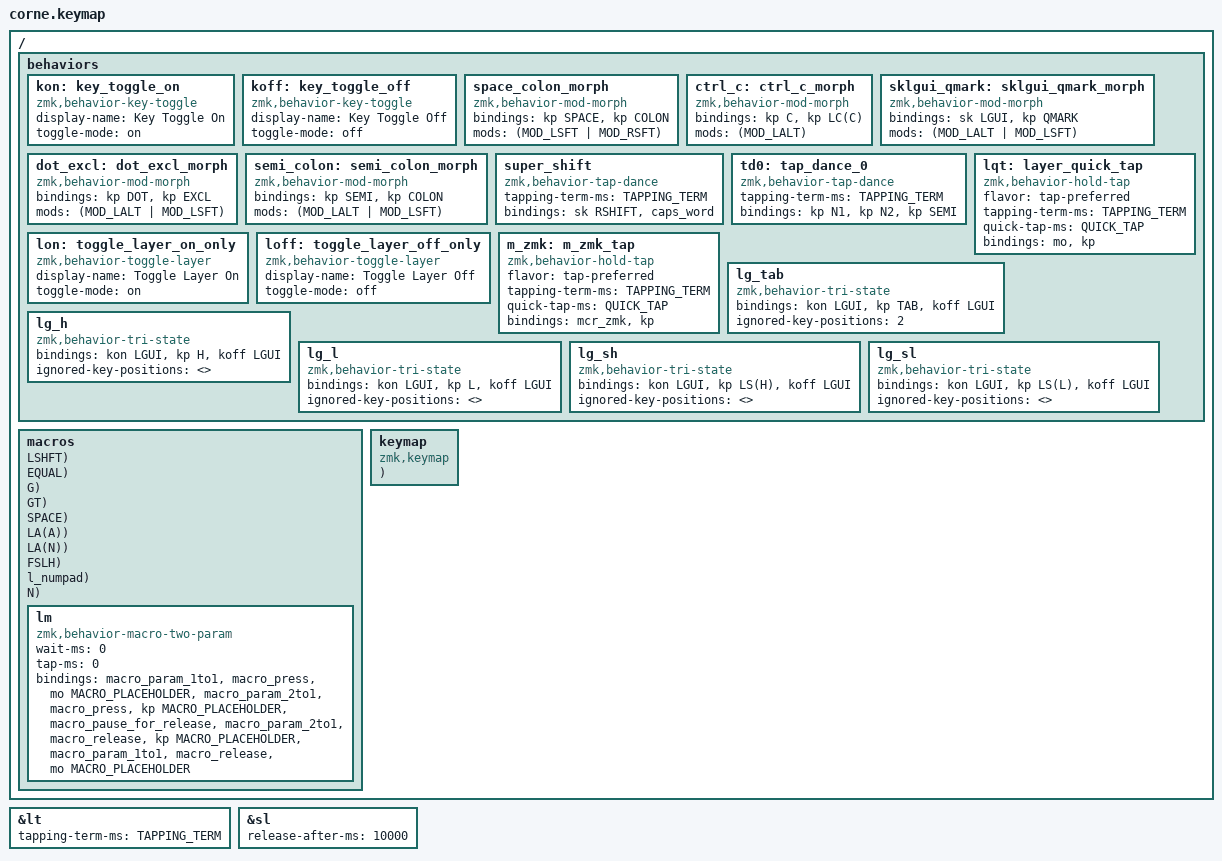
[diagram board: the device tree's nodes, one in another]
#include <behaviors.dtsi>
#include <dt-bindings/zmk/keys.h>
#include <dt-bindings/zmk/bt.h>

#define STRINGIFY(x) #x
#define EXPAND_AND_STRINGIFY(x) STRINGIFY(x)
#define MACRO(NAME, BINDINGS) \
mcr_##NAME: mcr_##NAME { \
   compatible = "zmk,behavior-macro"; \
   #binding-cells = <0>; \
   wait-ms = <20>; \
   tap-ms = <10>; \
   bindings = <BINDINGS>; \
}

#define hands(layer_name, \
   lt1, lt2, lt3, lt4, lt5, lt6, lm1, lm2, lm3, lm4, lm5, lm6, lb1, lb2, lb3, lb4, lb5, lb6, lth1, lth2, lth3, \
   rt1, rt2, rt3, rt4, rt5, rt6, rm1, rm2, rm3, rm4, rm5, rm6, rb1, rb2, rb3, rb4, rb5, rb6, rth1, rth2, rth3 \
) \
layer_name { \
   display-name = EXPAND_AND_STRINGIFY(layer_name); \
   bindings = < \
      lt1 lt2 lt3 lt4 lt5 lt6 rt1 rt2 rt3 rt4 rt5 rt6 lm1 lm2 lm3 lm4 lm5 lm6 \
      rm1 rm2 rm3 rm4 rm5 rm6 lb1 lb2 lb3 lb4 lb5 lb6 rb1 rb2 rb3 rb4 rb5 rb6 \
      lth1 lth2 lth3 rth1 rth2 rth3 \
   >; \
}

#define right(layer_name, \
   rt1, rt2, rt3, rt4, rt5, rt6, rm1, rm2, rm3, rm4, rm5, rm6, rb1, rb2, rb3, rb4, rb5, rb6, rth1, rth2, rth3 \
) \
layer_name { \
   display-name = EXPAND_AND_STRINGIFY(layer_name); \
   bindings = < \
      &trans     &trans &trans &trans &trans &trans rt1 rt2 rt3 rt4 rt5 rt6 \
      &to l_base &trans &trans &trans &trans &trans rm1 rm2 rm3 rm4 rm5 rm6 \
      &trans     &trans &trans &trans &trans &trans rb1 rb2 rb3 rb4 rb5 rb6 \
      &trans     &trans &trans rth1 rth2 rth3 \
   >; \
}

#define left(layer_name, \
   lt1, lt2, lt3, lt4, lt5, lt6, lm1, lm2, lm3, lm4, lm5, lm6, lb1, lb2, lb3, lb4, lb5, lb6, lth1, lth2, lth3 \
) \
layer_name { \
   display-name = EXPAND_AND_STRINGIFY(layer_name); \
   bindings = < \
      lt1 lt2 lt3 lt4 lt5 lt6 &trans &trans &trans &trans &trans &trans \
      lm1 lm2 lm3 lm4 lm5 lm6 &trans &trans &trans &trans &trans &trans \
      lb1 lb2 lb3 lb4 lb5 lb6 &trans &trans &trans &trans &trans &trans \
      lth1 lth2 lth3 &trans &trans &trans \
   >; \
}

#define l_base       0
#define l_reright    1
#define l_releft     2
#define l_code1      3
#define l_code2      4
#define l_term       5
#define l_symb1      6
#define l_symb2      7
#define l_os1        8
#define l_numpad     9
#define l_vimnav    10
#define l_arrows    11
#define l_toglayer  12

#define PRIOR_IDLE 125
#define TAPPING_TERM 200
#define QUICK_TAP 300

// #define PRIOR_IDLE 125
// #define TAPPING_TERM 250

// &mt {
   // tapping-term-ms = <TAPPING_TERM>;
   // require-prior-idle-ms = <PRIOR_IDLE>;
// };

&lt {
   tapping-term-ms = <TAPPING_TERM>;
   // require-prior-idle-ms = <PRIOR_IDLE>;
};

&sl {
    release-after-ms = <10000>;
};

/ {

   behaviors {
      kon: key_toggle_on {
         compatible = "zmk,behavior-key-toggle";
         #binding-cells = <1>;
         display-name = "Key Toggle On";
         toggle-mode = "on";
      };
      koff: key_toggle_off {
         compatible = "zmk,behavior-key-toggle";
         #binding-cells = <1>;
         display-name = "Key Toggle Off";
         toggle-mode = "off";
      };
      space_colon_morph: space_colon_morph {
         compatible = "zmk,behavior-mod-morph";
         #binding-cells = <0>;
         bindings = <&kp SPACE>, <&kp COLON>;
         mods = <(MOD_LSFT | MOD_RSFT)>;
      };
      ctrl_c: ctrl_c_morph {
         compatible = "zmk,behavior-mod-morph";
         #binding-cells = <0>;
         bindings = <&kp C>, <&kp LC(C)>;
         mods = <(MOD_LALT)>;
      };
      sklgui_qmark: sklgui_qmark_morph {
         compatible = "zmk,behavior-mod-morph";
         #binding-cells = <0>;
         bindings = <&sk LGUI>, <&kp QMARK>;
         mods = <(MOD_LALT | MOD_LSFT)>;
      };
      dot_excl: dot_excl_morph {
         compatible = "zmk,behavior-mod-morph";
         #binding-cells = <0>;
         bindings = <&kp DOT>, <&kp EXCL>;
         mods = <(MOD_LALT | MOD_LSFT)>;
      };
      semi_colon: semi_colon_morph {
         compatible = "zmk,behavior-mod-morph";
         #binding-cells = <0>;
         bindings = <&kp SEMI>, <&kp COLON>;
         mods = <(MOD_LALT | MOD_LSFT)>;
      };
      super_shift: super_shift {
         compatible = "zmk,behavior-tap-dance";
         #binding-cells = <0>;
         tapping-term-ms = <TAPPING_TERM>;
         bindings = <&sk RSHIFT>, <&caps_word>;
      };
      td0: tap_dance_0 {
         compatible = "zmk,behavior-tap-dance";
         #binding-cells = <0>;
         tapping-term-ms = <TAPPING_TERM>;
         bindings = <&kp N1>, <&kp N2>, <&kp SEMI>;
      };
      lqt: layer_quick_tap {
         compatible = "zmk,behavior-hold-tap";
         #binding-cells = <2>;
         flavor = "tap-preferred";
         tapping-term-ms = <TAPPING_TERM>;
         quick-tap-ms = <QUICK_TAP>;
         bindings = <&mo>, <&kp>;
      };
      lon: toggle_layer_on_only {
         compatible = "zmk,behavior-toggle-layer";
         #binding-cells = <1>;
         display-name = "Toggle Layer On";
         toggle-mode = "on";
      };
      loff: toggle_layer_off_only {
         compatible = "zmk,behavior-toggle-layer";
         #binding-cells = <1>;
         display-name = "Toggle Layer Off";
         toggle-mode = "off";
      };
      m_zmk: m_zmk_tap {
         compatible = "zmk,behavior-hold-tap";
         #binding-cells = <2>;
         flavor = "tap-preferred";
         tapping-term-ms = <TAPPING_TERM>;
         quick-tap-ms = <QUICK_TAP>;
         bindings = <&mcr_zmk>, <&kp>;
      };
      lg_tab: lg_tab {
         compatible = "zmk,behavior-tri-state";
         #binding-cells = <0>;
         bindings = <&kon LGUI>, <&kp TAB>, <&koff LGUI>;
         ignored-key-positions = <2>;
      };
      // this almost works but an extra koff gets queued on only one direction and eats the next lgui
      // ls_lg_tab: ls_lg_tab {
         // compatible = "zmk,behavior-tri-state";
         // #binding-cells = <0>;
         // bindings = <&kon LGUI>, <&kp LS(TAB)>, <&mcr_lgoff>;
         // ignored-key-positions = <3>;
      // };
      lg_h: lg_h {
         compatible = "zmk,behavior-tri-state";
         #binding-cells = <0>;
         bindings = <&kon LGUI>, <&kp H>, <&koff LGUI>;
         ignored-key-positions = <>;
      };
      lg_l: lg_l {
         compatible = "zmk,behavior-tri-state";
         #binding-cells = <0>;
         bindings = <&kon LGUI>, <&kp L>, <&koff LGUI>;
         ignored-key-positions = <>;
      };
      lg_sh: lg_sh {
         compatible = "zmk,behavior-tri-state";
         #binding-cells = <0>;
         bindings = <&kon LGUI>, <&kp LS(H)>, <&koff LGUI>;
         ignored-key-positions = <>;
      };
      lg_sl: lg_sl {
         compatible = "zmk,behavior-tri-state";
         #binding-cells = <0>;
         bindings = <&kon LGUI>, <&kp LS(L)>, <&koff LGUI>;
         ignored-key-positions = <>;
      };
      // num_td_a: num_td_a {
         // compatible = "zmk,behavior-tap-dance";
         // label = "num_td";
         // #binding-cells = <0>;
         // tapping-term-ms = <TAPPING_TERM>;
         // bindings =
            // <&lt l_numpad A>,
            // <&lon l_numpad>;
      // };
      // alt_a_td_fix: alt_a_td_fix {
         // compatible = "zmk,behavior-mod-morph";
         // #binding-cells = <0>;
         // bindings =  <&num_td_a>, <&kp LA(A)>;
         // mods = <MOD_LALT>;
      // };
   };

   macros {
      MACRO(zmk, &macro_press &kp LSHFT &macro_tap &kp Z &kp M &kp K &macro_release &kp LSHFT);
      MACRO(shift_tab, &macro_press &kp LSHFT &macro_tap &kp TAB &macro_release &kp LSHFT);
      MACRO(seq, &macro_tap &kp EQUAL &kp EQUAL &kp EQUAL);
      MACRO(sne, &macro_tap &kp EXCL &kp EQUAL &kp EQUAL);
      MACRO(lte, &macro_tap &kp LT &kp EQUAL);
      MACRO(gte, &macro_tap &kp GT &kp EQUAL);
      MACRO(gg, &macro_tap &kp G &kp G);
      MACRO(peq, &macro_tap &kp PLUS &kp EQUAL);
      MACRO(meq, &macro_tap &kp MINUS &kp EQUAL);
      MACRO(arwfn, &macro_tap &kp EQUAL &kp GT);
      MACRO(the, &macro_tap &kp T &kp H &kp E &kp SPACE);
      MACRO(ca_ca, &macro_tap &kp LA(A) &kp LA(A));
      MACRO(ca_cn, &macro_tap &kp LA(A) &kp LA(N));
      MACRO(dot_fs, &macro_tap &kp DOT &kp FSLH);
      MACRO(goto_line, &macro_tap &kp SEMI &kp L &kp L &to l_numpad);
      MACRO(endl, &macro_tap &kp BSLH &kp N);
      // MACRO(lgoff, &macro_tap &koff LGUI &koff LGUI);
      /**
      * Temporarily switches to a layer (`&mo`) while a modifier is held.
      * Analogous to QMK's `LM()`, using a parameterized macro.
      *
      * Params:
      *  1. Layer to switch to
      *  2. Modifier to press while layer is active
      *
      * Example:
      *  `&lm NUM_LAYER LSHIFT`
      */
      lm: lm {
         compatible = "zmk,behavior-macro-two-param";
         wait-ms = <0>;
         tap-ms = <0>;
         #binding-cells = <2>;
         bindings
         = <&macro_param_1to1>
         , <&macro_press &mo MACRO_PLACEHOLDER>
         , <&macro_param_2to1>
         , <&macro_press &kp MACRO_PLACEHOLDER>
         , <&macro_pause_for_release>
         , <&macro_param_2to1>
         , <&macro_release &kp MACRO_PLACEHOLDER>
         , <&macro_param_1to1>
         , <&macro_release &mo MACRO_PLACEHOLDER>
         ;
      };
   };

   keymap {

      compatible = "zmk,keymap";

      hands( base,

         &kp TAB       , &lt l_os1 Q    , &kp W          , &lt l_arrows E , &kp R           , &kp T         ,
         &mt LALT ESC  , &lt l_numpad A , &lt l_term S   , &lqt l_code2 D , &lt l_code1 F   , &kp G         ,
         &super_shift  , &kp Z          , &kp X          , &ctrl_c        , &lt l_reright V , &kp B         ,
         &sk LGUI      , &kp SPACE      , &kp SPACE      ,
         // &none      , &none          , &none          ,
         // &none      , &kp SPACE      , &none          ,
         // &kp LGUI   , &kp SPACE      , &kp LALT       ,

         &kp Y        , &kp U          , &kp I          , &kp O          , &kp P           , &lon l_vimnav ,
         &kp H        , &lqt l_symb1 J , &lqt l_symb2 K , &kp L          , &semi_colon     , &sl l_toglayer,
         &kp N        , &lt l_releft M , &kp COMMA      , &dot_excl      , &sklgui_qmark   , &none         ,
         &none        , &none          , &none
         // &lm l_releft LGUI , &none          , &none
         // &none             , &none          , &none
         // &kp SPACE         , &kp SPACE      , &kp SPACE
         // &kp SPACE         , &none          , &none
         // &none             , &none          , &none
         // &kp SPACE         , &ctrlentbspc   , &kp RGUI

         /*&trans,&trans,&trans,&trans,&trans,&trans,*/
         /*&trans,&trans,&trans,&trans,&trans,&trans,*/
         /*&trans,&trans,&trans,&trans,&trans,&trans,*/
         /*&trans,&trans,&trans,*/
         /*&trans,&trans,&trans,&trans,&trans,&trans,*/
         /*&trans,&trans,&trans,&trans,&trans,&trans,*/
         /*&trans,&trans,&trans,&trans,&trans,&trans,*/
         /*&trans,&trans,&trans*/

      );

      right( reright,
         &none  , &none        , &kp LC(U) , &none       , &none    , &none ,
         &none  , &kp BSPC     , &kp RET   , &kp LA(H)   , &kp FSLH , &none ,
         &none  , &kp LA(BSPC) , &kp LC(D) , &mcr_dot_fs , &none    , &none ,
         &trans , &trans       , &trans
      );

      hands( releft,
         // &none , &none             , &kp LS(LG(TAB)) , &kp LG(TAB)       , &none         , &none      ,
         // &none , &kp LG(H)         , &kp LA(H)       , &kp LA(L)         , &kp LG(L)     , &none      ,
         // &none , &none             , &none           , &kp LS(LA(LG(K))) , &kp LA(LG(K)) , &none      ,

         &none    , &lg_sh            , &kp LS(TAB)     , &lg_tab           , &lg_sl        , &none      ,
         &none    , &lg_h             , &kp LA(H)       , &kp LA(L)         , &lg_l         , &none      ,
         &none    , &kp LS(LA(LG(Z))) , &none           , &kp LA(LG(Z))     , &mcr_ca_ca    , &mcr_ca_cn ,
         &trans   , &trans            , &trans          ,

         &trans   , &trans            , &trans          , &trans            , &trans        , &trans     ,
         &trans   , &trans            , &trans          , &trans            , &trans        , &trans     ,
         &trans   , &trans            , &trans          , &trans            , &trans        , &trans     ,
         &trans   , &trans            , &trans
      );


      right( code_1,
         &none  , &none     , &kp LPAR , &kp RPAR , &kp CARET  , &none    ,
         &none  , &kp UNDER , &kp LBRC , &kp RBRC , &kp STAR   , &none    ,
         &none  , &kp EQUAL , &kp LBKT , &kp RBKT , &kp DOLLAR , &mcr_zmk ,
         &trans , &trans    , &trans
      );

      right( code_2,
         &none  , &none     , &kp AMPS          , &kp PIPE  , &none            , &none     ,
         &none  , &kp UNDER , &kp DOUBLE_QUOTES , &kp GRAVE , &kp SINGLE_QUOTE , &mcr_endl ,
         &none  , &kp MINUS , &kp PLUS          , &kp EXCL  , &kp BSLH         , &none     ,
         &trans , &trans    , &trans
      );

      // &macro_tap &kp EQUAL &kp EQUAL &kp EQUAL
      // &macro_tap &kp MINUS &kp GT                 // ->
      // &macro_tap &kp AMPERSAND &kp AMPERSAND      // &&

      right( term_1,
         &none     , &kp PLUS  , &kp AMPS , &kp PIPE , &kp EQUAL , &none     ,
         &kp TILDE , &kp UNDER , &kp EXCL , &kp STAR , &kp FSLH  , &kp PRCNT ,
         &none     , &kp MINUS , &kp AT   , &kp HASH , &kp BSLH  , &none     ,
         &trans    , &trans    , &trans
      );

      left( symb_1,
         &none  , &none    , &mcr_lte , &mcr_gte , &none      , &none ,
         &none  , &kp LT   , &mcr_sne , &mcr_seq , &kp GT     , &none ,
         &none  , &mcr_meq , &mcr_peq , &none    , &mcr_arwfn , &none ,
         &trans , &trans   , &trans
      );

      left( symb_2,
         &none  , &none  , &none  , &none , &none , &none ,
         &none  , &none  , &none  , &none , &none , &none ,
         &none  , &none  , &none  , &none , &none , &none ,
         &trans , &trans , &trans
      );

      hands( os_1,
         &bootloader , &trans     , &trans       , &trans       , &trans , &trans      ,
         &trans      , &trans     , &trans       , &trans       , &trans , &trans      ,
         &trans      , &trans     , &trans       , &trans       , &trans , &trans      ,
         &trans      , &trans     , &trans       ,

         &none       , &kp C_MUTE , &kp C_VOL_DN , &kp C_VOL_UP , &none  , &bootloader ,
         &none       , &kp C_PREV , &kp C_PP     , &kp C_NEXT   , &none  , &none       ,
         &none       , &none      , &kp C_BRI_DN , &kp C_BRI_UP , &none  , &none       ,
         &trans      , &trans     , &trans
      );

      hands( numpad_1,
         &none      , &none   , &kp DOLLAR , &kp RET   , &none     , &none     ,
         &to l_base , &trans  , &kp MINUS  , &kp PLUS  , &kp STAR  , &kp FSLH  ,
         &none      , &none   , &none      , &none     , &kp UNDER , &none     ,
         &trans     , &trans  , &trans     ,

         &none      , &kp N7  , &kp N8     , &kp N9    , &kp EQUAL , &none     ,
         &kp BSPC   , &kp N4  , &kp N5     , &kp N6    , &kp N0    , &kp PRCNT ,
         &kp EQUAL  , &kp N1  , &kp N2     , &kp N3    , &kp DOT   , &none     ,
         &kp RET    , &kp RET , &kp RET
      );

      hands( vimnav_1,
         &none      , &none     , &none     , &none     , &none , &none          ,
         &to l_base , &none     , &none     , &none     , &none , &none          ,
         &none      , &none     , &none     , &none     , &none , &none          ,
         &none      , &kp LA(D) , &none     ,

         &none      , &none     , &mcr_gg   , &kp LS(G) , &none , &loff l_vimnav ,
         &none      , &kp LA(D) , &kp LA(U) , &none     , &none , &none          ,
         &none      , &kp LA(J) , &kp LA(K) , &none     , &none , &none          ,
         &none      , &trans    , &trans
      );

      right( arrows_1,
         &none,           &none,           &none,          &none,          &none,           &none,
         &kp LEFT,        &kp DOWN,        &kp UP,         &kp RIGHT,      &none,           &none,
         &none,           &none,           &none,          &none,          &none,           &none,
         &trans,          &trans,          &trans
      );

      hands( toglayer,
         &none  , &none        , &none      , &none       , &none         , &none ,
         &none  , &to l_numpad , &to l_term , &to l_code2 , &to l_code1   , &none ,
         &none  , &none        , &none      , &none       , &to l_reright , &none ,
         &trans , &trans       , &trans     ,

         &none  , &none        , &none      , &none       , &none         , &none ,
         &none  , &none        , &none      , &none       , &none         , &none ,
         &none  , &none        , &none      , &none       , &none         , &none ,
         &trans , &trans       , &trans
      );
   };
};
